# MINI51AN_v1 register map
File version: 1.0
Registers are 32-bit, read-write, reset 0x0 unless marked. A register's access mark holds for its fields unless they carry their own. Offsets are from the block's base; [hi:lo] are bit positions; {n}, {i} and the like mark numbered series; 'fields as' and 'values as' point back to an identical list.

## I2C — I2C Register Map
Base 0x40020000
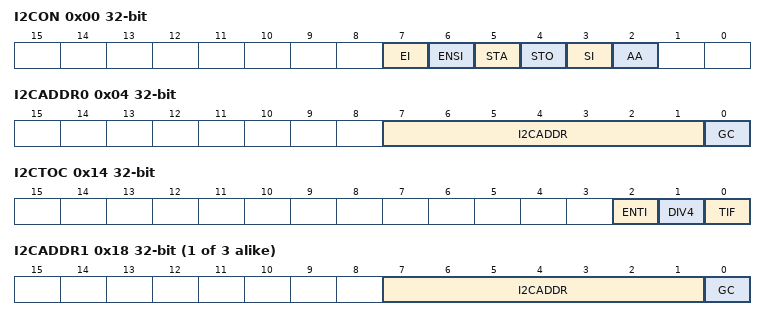
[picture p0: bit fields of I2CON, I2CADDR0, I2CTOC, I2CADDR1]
0x00 I2CON — I2C Control Register
  [7] EI — Enable Interrupt
    0=I2C interrupt Disabled; 1=I2C interrupt Enabled
  [6] ENSI — I2C Controller Enable Bit
    0=Disabled; 1=Enabled
  [5] STA — I2C START Control Bit. Setting STA to logic 1 will enter Master mode. I2C hardware sends a START or repeats the START condition to bus when the bus is free.
  [4] STO — I2C STOP Control Bit. In Master mode, setting STO to transmit a STOP condition to bus then I2C hardware will check the bus condition if a STOP condition is detected this bit will be cleared by hardware automatically. In Slave mode, setting STO resets I2C hardware to the defined "not addressed" Slave mode. This means it is NO LONGER in the Slave receiver mode to receive data from the master transmit device.
  [3] SI — I2C Interrupt Flag. When a new I2C state is present in the I2CSTATUS register, the SI flag is set by hardware, and if bit EI (I2CON[7]) is set, the I2C interrupt is requested. SI must be cleared by software. Software can write 1 to clear this bit.
  [2] AA — Assert Acknowledge Control Bit
0x04 I2CADRR0 — I2C Slave Address Register 0
0x04 I2CADDR0 (alternate view of I2CADRR0) — I2C Slave Address Register 0
  [7:1] I2CADDR — I2C Address Register. The content of this register is irrelevant when I2C is in Master mode. In Slave mode, the seven most significant bits must be loaded with the MCU's own address. The I2C hardware will react if either of the address is matched.
  [0] GC — General Call Function
    0=Disable General Call Function; 1=Enable General Call Function
0x08 I2CDAT — I2C DATA Register
  [7:0] I2CDAT — I2C Data Register. Bit [7:0] is located with the 8-bit transferred data of the I2C serial port.
0x0C I2CSTATUS ro reset 0xF8
  [7:0] I2CSTATUS — I2C Status Register. The status register of I2C controller:
0x10 I2CLK — I2C Clock Divided Register
  [7:0] I2CLK
0x14 I2CTOC — I2C Time-out Counter Register
  [2] ENTI — Time-out Counter Enabled. When enabled, the 14-bit time-out counter will start counting when SI is clear. Setting flag SI to high will reset counter and re-start up counting after SI is cleared.
    0=Disabled; 1=Enabled
  [1] DIV4 — Time-out Counter Input Clock Divided by 4. When enabled, the time-out period is prolong 4 times.
    0=Disabled; 1=Enabled
  [0] TIF — Time-out Flag
    0=Software can clear the flag by writing 1 to this flag when TIF is set; 1=Time-out flag is set by hardware. It can interrupt CPU
{0x14+4i} I2CADDR{i} (i=1..3) — I2C Slave Address Register {i}
  fields as I2CADDR0
{0x24+4i} I2CADM{i} (i=0..3) — I2C Slave Address Mask Register {i}
  [7:1] I2CADMx — I2C Address Mask register. I2C bus controller supports multiple address recognition with four address mask registers. When the bit in the address mask register is set to 1, the received corresponding address bit is don't-care. If the bit is set to 0, the received corresponding register bit should be exactly the same as address register.
    0=Mask Disabled (the received corresponding register bit should be exactly the same as address register); 1=Mask Enabled (the received corresponding address bit is don't care)
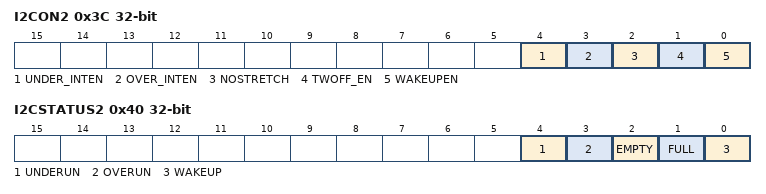
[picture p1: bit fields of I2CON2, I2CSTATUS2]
0x3C I2CON2 — I2C Control Register 2
  [4] UNDER_INTEN — I2C UNDER RUN Interrupt Control Bit. Setting UNDER_INTEN to logic 1 will send a interrupt to system when the TWOFF bit is enabled and there is under run event happened in transmitted fifo.
  [3] OVER_INTEN — I2C OVER RUN Interrupt Control Bit. Setting OVER_INTEN to logic 1 will send a interrupt to system when the TWOFF bit is enabled and there is over run event in received fifo.
  [2] NOSTRETCH — NO STRETCH the I2C BUS
    0=The I2C SCL bus is stretched by hardware if the SI is not cleared in master mode; 1=The I2C SCL bus is not stretched by hardware if the SI is not cleared in master mode
  [1] TWOFF_EN — TWO LEVEL FIFO Enable
    0=Disabled; 1=Enabled
  [0] WAKEUPEN — Wake-Up Enable. The system can be wake up by I2C bus when the system is set into power mode and the received data matched one of the addresses in Address Register.
    0=Disabled; 1=Enabled
0x40 I2CSTATUS2 — I2C Status Register 2
  [4] UNDERUN — I2C UNDER RUN Status Bit
  [3] OVERUN — I2C OVER RUN Status Bit
  [2] EMPTY — TWO LEVEL FIFO EMPTY. This bit is set when RX_POINTER is equal to 0.
  [1] FULL — TWO LEVEL FIFO FULL. This bit is set when TX_POINTER is equal to 2
  [0] WAKEUP — Wake Up. This bit indicates the wake-up function is done.
